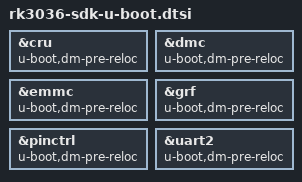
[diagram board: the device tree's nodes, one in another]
&cru {
	u-boot,dm-pre-reloc;
};

&dmc {
	u-boot,dm-pre-reloc;
};

&emmc {
	u-boot,dm-pre-reloc;
};

&grf {
	u-boot,dm-pre-reloc;
};

&pinctrl {
	u-boot,dm-pre-reloc;
};

&uart2 {
	u-boot,dm-pre-reloc;
};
